# ATSAM4LS8B register map
Vendor: Atmel Corporation; Series: SAM4L; File version: A
CPU: CM4 r0p1, little endian, MPU, no FPU, 4 interrupt priority bits
Registers are 32-bit, write-only, reset 0x0 unless marked. A register's access mark holds for its fields unless they carry their own. Offsets are from the block's base; [hi:lo] are bit positions; {n}, {i} and the like mark numbered series.

## BPM — Backup Power Manager
Base 0x400F0000; register names take the prefix BPM_
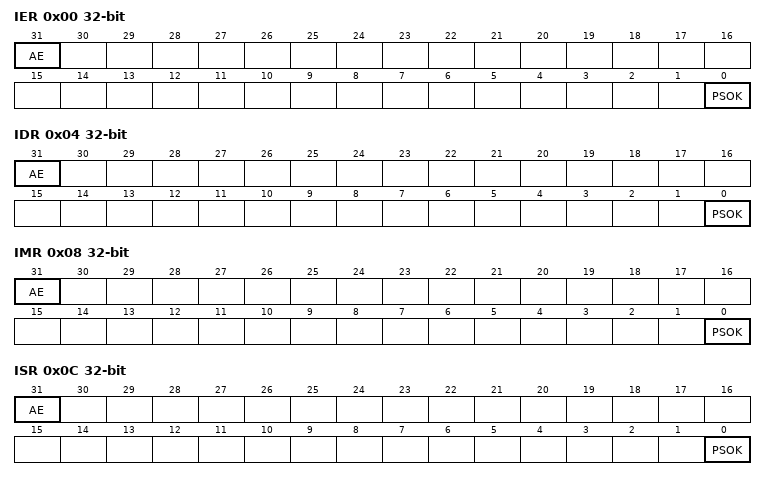
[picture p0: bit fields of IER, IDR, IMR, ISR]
0x00 IER — Interrupt Enable Register
  [31] AE — Access Error Interrupt Enable
  [0] PSOK — Power Scaling OK Interrupt Enable
0x04 IDR — Interrupt Disable Register
  [31] AE — Access Error Interrupt Disable
  [0] PSOK — Power Scaling OK Interrupt Disable
0x08 IMR ro — Interrupt Mask Register
  [31] AE — Access Error Interrupt Mask
  [0] PSOK — Power Scaling OK Interrupt Mask
0x0C ISR ro — Interrupt Status Register
  [31] AE — Access Error Interrupt Status
  [0] PSOK — Power Scaling OK Interrupt Status
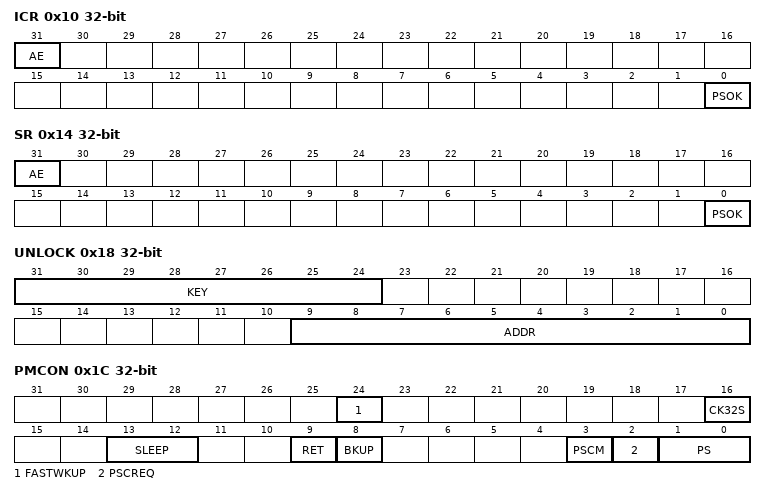
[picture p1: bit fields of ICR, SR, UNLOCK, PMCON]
0x10 ICR — Interrupt Clear Register
  [31] AE — Access Error Interrupt Status Clear
  [0] PSOK — Power Scaling OK Interrupt Status Clear
0x14 SR ro — Status Register
  [31] AE — Access Error
  [0] PSOK — Power Scaling OK Status
0x18 UNLOCK
  [31:24] KEY — Unlock Key
  [9:0] ADDR — Unlock Address
0x1C PMCON rw — Power Mode Control Register
  [24] FASTWKUP — Fast Wakeup
  [16] CK32S — 32Khz-1Khz Clock Source Selection
  [13:12] SLEEP — SLEEP mode Configuration
  [9] RET — RETENTION Mode
  [8] BKUP — BACKUP Mode
  [3] PSCM — Power Scaling Change Mode
  [2] PSCREQ — Power Scaling Change Request
  [1:0] PS — Power Scaling Configuration Value
0x28 BKUPWCAUSE ro — Backup Wake up Cause Register
0x2C BKUPWEN rw — Backup Wake up Enable Register
0x30 BKUPPMUX rw — Backup Pin Muxing Register
  [8:0] BKUPPMUX — Backup Pin Muxing
0x34 IORET rw — Input Output Retention Register
  [0] RET — Retention on I/O lines after waking up from the BACKUP mode
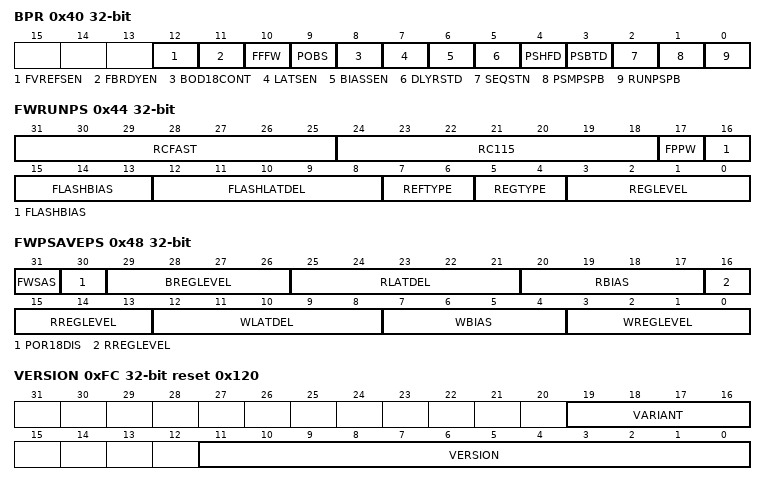
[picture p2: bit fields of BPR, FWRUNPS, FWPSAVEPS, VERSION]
0x40 BPR rw — Bypass Register
  [12] FVREFSEN — Flash Vref Switch Enable
  [11] FBRDYEN — Flash Bias Ready Enable
  [10] FFFW — Force Flash Fast Wakeup
  [9] POBS — Pico Uart Observability
  [8] BOD18CONT — BOD18 in continuous mode not disabled in WAIT/RET/BACKUP modes
  [7] LATSEN — Latdel Switch Enable
  [6] BIASSEN — Bias Switch Enable
  [5] DLYRSTD — Delaying Reset Disable
  [4] PSHFD — Power Scaling Halt Flash Until VREGOK Disable
  [3] PSBTD — Power Scaling Bias Timing Disable
  [2] SEQSTN — Sequencial Startup from ULP (Active Low)
  [1] PSMPSPB — Power Save Mode Power Scaling Preset Bypass
  [0] RUNPSPB — Run Mode Power Scaling Preset Bypass
0x44 FWRUNPS ro — Factory Word Run PS Register
  [31:25] RCFAST — RCFAST Calibration Value
  [24:18] RC115 — RC 115KHZ Calibration Value
  [17] FPPW — Flash Pico Power Mode
  [16:13] FLASHBIAS — Flash Bias Value
  [12:8] FLASHLATDEL — Flash Latch Delay Value
  [7:6] REFTYPE — Reference Type
    0=BOTH; 1=BG; 2=LPBG; 3=INTERNAL
  [5:4] REGTYPE — Regulator Type
    0=NORMAL; 1=LP; 2=XULP
  [3:0] REGLEVEL — Regulator Voltage Level
0x48 FWPSAVEPS ro — Factory Word Power Save PS Register
  [31] FWSAS — Flash Wait State Automatic Switching
  [30] POR18DIS — POR 18 Disable
  [29:26] BREGLEVEL — Backup mode Regulator Level
  [25:21] RLATDEL — Flash Latdel in Retention mode
  [20:17] RBIAS — Bias in Retention mode
  [16:13] RREGLEVEL — Retention mode Regulator Level
  [12:8] WLATDEL — Flash Latdel in wait mode
  [7:4] WBIAS — Bias in wait mode
  [3:0] WREGLEVEL — Wait mode Regulator Level
0xFC VERSION ro reset 0x120
  [19:16] VARIANT — Variant Number
  [11:0] VERSION — Version Number

## CATB — Capacitive Touch Module B
Base 0x40070000; register names take the prefix CATB_
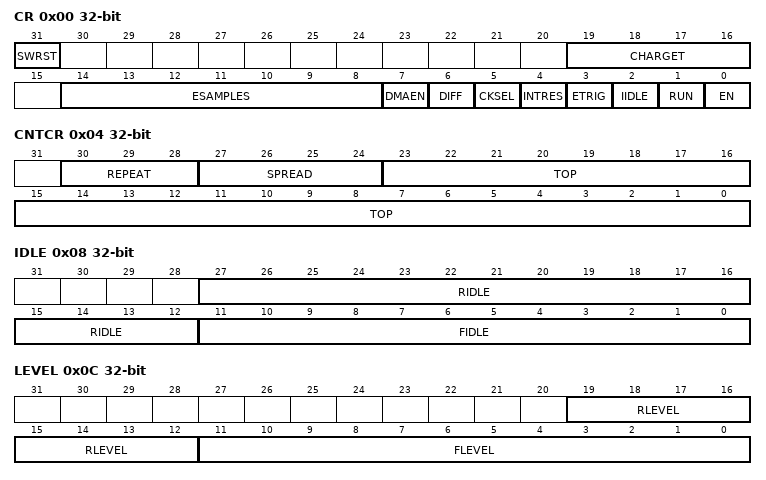
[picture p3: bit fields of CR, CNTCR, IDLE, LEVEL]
0x00 CR rw — Control Register
  [31] SWRST — Software Reset
  [19:16] CHARGET — Charge Time
  [14:8] ESAMPLES — Number of Event Samples
  [7] DMAEN — DMA Enable
  [6] DIFF — Differential Mode
  [5] CKSEL — Clock Select
  [4] INTRES — Internal Resistors
  [3] ETRIG — Event Triggered Operation
  [2] IIDLE — Initialize Idle Value
  [1] RUN — Start Operation
  [0] EN — Module Enable
0x04 CNTCR rw — Counter Control Register
  [30:28] REPEAT — Repeat Measurements
  [27:24] SPREAD — Spread Spectrum
  [23:0] TOP — Counter Top Value
0x08 IDLE rw — Sensor Idle Level
  [27:12] RIDLE — Integer Sensor Idle
  [11:0] FIDLE — Fractional Sensor Idle
0x0C LEVEL ro — Sensor Relative Level
  [19:12] RLEVEL — Integer Sensor Level
  [11:0] FLEVEL — Fractional Sensor Level
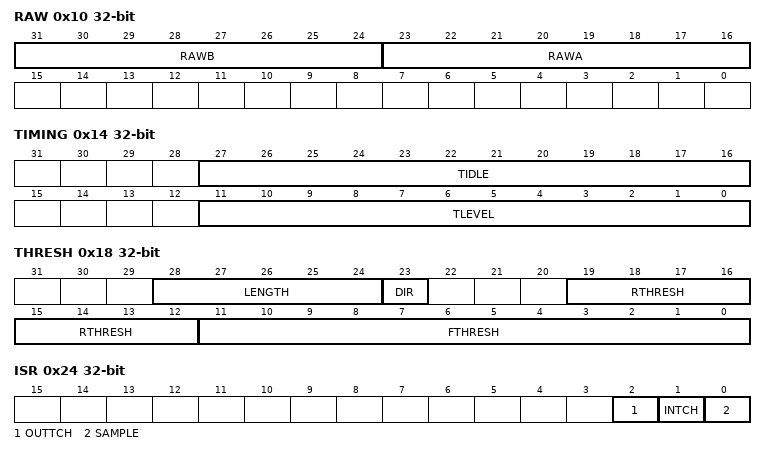
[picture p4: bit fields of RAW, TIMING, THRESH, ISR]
0x10 RAW ro — Sensor Raw Value
  [31:24] RAWB — Last Sensor Raw Value
  [23:16] RAWA — Current Sensor Raw Value
0x14 TIMING rw — Filter Timing Register
  [27:16] TIDLE — Idle Smoothening
  [11:0] TLEVEL — Relative Level Smoothing
0x18 THRESH rw — Threshold Register
  [28:24] LENGTH — Threshold Length
  [23] DIR — Threshold Direction
  [19:12] RTHRESH — Rational part of Threshold Value
  [11:0] FTHRESH — Fractional part of Threshold Value
0x1C PINSEL rw — Pin Selection Register
  [7:0] PINSEL — Pin Select
0x20 DMA rw — Direct Memory Access Register
  [31:0] DMA — Direct Memory Access
0x24 ISR ro — Interrupt Status Register
  [2] OUTTCH — Out-of-Touch Interrupt Status
  [1] INTCH — In-touch Interrupt Status
  [0] SAMPLE — Sample Ready Interrupt Status
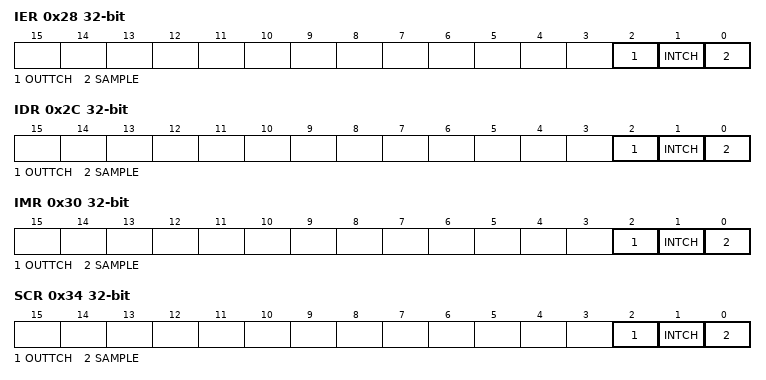
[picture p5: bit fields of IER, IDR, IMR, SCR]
0x28 IER — Interrupt Enable Register
  [2] OUTTCH — Out-of-Touch Interrupt Enable
  [1] INTCH — In-touch Interrupt Enable
  [0] SAMPLE — Sample Ready Interrupt Enable
0x2C IDR — Interrupt Disable Register
  [2] OUTTCH — Out-of-Touch Interrupt Disable
  [1] INTCH — In-touch Interrupt Disable
  [0] SAMPLE — Sample Ready Interrupt Disable
0x30 IMR ro — Interrupt Mask Register
  [2] OUTTCH — Out-of-Touch Interrupt Mask
  [1] INTCH — In-touch Interrupt Mask
  [0] SAMPLE — Sample Ready Interrupt Mask
0x34 SCR — Status Clear Register
  [2] OUTTCH — Out-of-Touch
  [1] INTCH — In-touch
  [0] SAMPLE — Sample Ready
{0x40+4i} INTCH{i} (i=0..0) ro — In-Touch Status Register
  [31:0] INTCH — In-Touch
{0x50+4i} INTCHCLR{i} (i=0..0) — In-Touch Status Clear Register
  [31:0] INTCHCLR — In-Touch Clear
{0x60+4i} OUTTCH{i} (i=0..0) ro — Out-of-Touch Status Register
  [31:0] OUTTCH — Out-of-Touch
{0x70+4i} OUTTCHCLR{i} (i=0..0) — Out-of-Touch Status Clear Register
  [31:0] OUTTCHCLR — Out of Touch
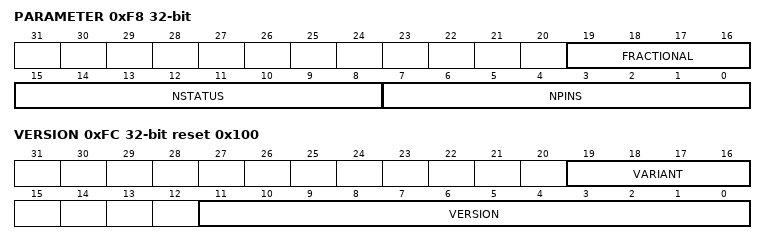
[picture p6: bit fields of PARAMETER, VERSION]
0xF8 PARAMETER ro
  [19:16] FRACTIONAL — Number of Fractional bits
  [15:8] NSTATUS — Number of Status bits
  [7:0] NPINS — Number of Pins
0xFC VERSION ro reset 0x100
  [19:16] VARIANT — Variant number
  [11:0] VERSION — Version number

## Notices in the file
Atmel Microcontroller Software Support
Copyright (c) 2016 Atmel Corporation,
a wholly owned subsidiary of Microchip Technology Inc.
Licensed under the Apache License, Version 2.0 (the "License");
you may not use this file except in compliance with the License.
You may obtain a copy of the Licence at
http://www.apache.org/licenses/LICENSE-2.0
Unless required by applicable law or agreed to in writing, software
distributed under the License is distributed on an "AS IS" BASIS,
WITHOUT WARRANTIES OR CONDITIONS OF ANY KIND, either express or implied.
See the License for the specific language governing permissions and
limitations under the License.
